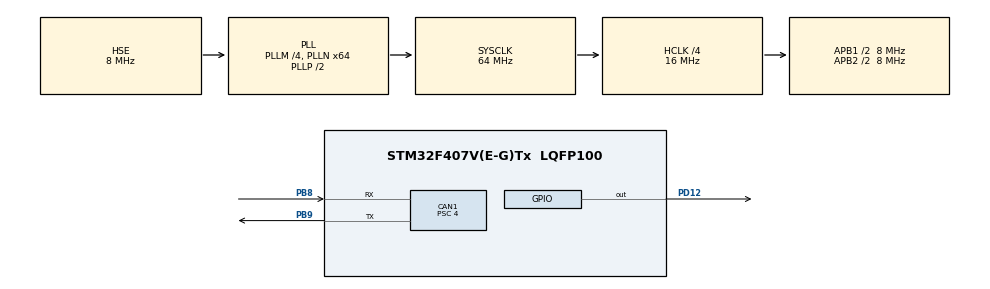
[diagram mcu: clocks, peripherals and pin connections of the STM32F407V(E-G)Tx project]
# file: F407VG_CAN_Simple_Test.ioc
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CAN1.BS1=CAN_BS1_2TQ
CAN1.CalculateTimeQuantum=500.0
CAN1.Mode=CAN_MODE_NORMAL
CAN1.NART=ENABLE
CAN1.Prescaler=4
CAN1.SJW=CAN_SJW_1TQ
Mcu.Family=STM32F4
Mcu.Name=STM32F407V(E-G)Tx
Mcu.Package=LQFP100
NVIC.PriorityGroup=NVIC_PRIORITYGROUP_4
NVIC.TIM1_UP_TIM10_IRQn=true\:0\:0\:false\:false\:true\:false\:true
NVIC.TimeBase=TIM1_UP_TIM10_IRQn
NVIC.TimeBaseIP=TIM1
PA13.Mode=Trace_Asynchronous_SW
PA13.Signal=SYS_JTMS-SWDIO
PA14.Mode=Trace_Asynchronous_SW
PA14.Signal=SYS_JTCK-SWCLK
PB3.Mode=Trace_Asynchronous_SW
PB3.Signal=SYS_JTDO-SWO
PB8.Mode=Master
PB8.Signal=CAN1_RX
PB9.Mode=Master
PB9.Signal=CAN1_TX
PD12.Signal=GPIO_Output
PH0-OSC_IN.Mode=HSE-External-Oscillator
PH0-OSC_IN.Signal=RCC_OSC_IN
PH1-OSC_OUT.Mode=HSE-External-Oscillator
PH1-OSC_OUT.Signal=RCC_OSC_OUT
ProjectManager.HeapSize=0x200
ProjectManager.StackSize=0x400
ProjectManager.TargetToolchain=STM32CubeIDE
RCC.48MHZClocksFreq_Value=32000000
RCC.AHBCLKDivider=RCC_SYSCLK_DIV4
RCC.AHBFreq_Value=16000000
RCC.APB1CLKDivider=RCC_HCLK_DIV2
RCC.APB1Freq_Value=8000000
RCC.APB1TimFreq_Value=16000000
RCC.APB2CLKDivider=RCC_HCLK_DIV2
RCC.APB2Freq_Value=8000000
RCC.APB2TimFreq_Value=16000000
RCC.CortexFreq_Value=16000000
RCC.HCLKFreq_Value=16000000
RCC.HSE_VALUE=8000000
RCC.HSI_VALUE=16000000
RCC.LSE_VALUE=32768
RCC.PLLM=4
RCC.PLLN=64
RCC.PLLSourceVirtual=RCC_PLLSOURCE_HSE
RCC.SYSCLKFreq_VALUE=64000000
RCC.SYSCLKSource=RCC_SYSCLKSOURCE_PLLCLK
RCC.VCOOutputFreq_Value=128000000
VP_SYS_VS_tim1.Mode=TIM1
board=custom

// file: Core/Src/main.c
/* USER CODE BEGIN Header */
/**
  ******************************************************************************
  * @file           : main.c
  * @brief          : Main program body
  ******************************************************************************
  * @attention
  *
  * <h2><center>&copy; Copyright (c) 2020 STMicroelectronics.
  * All rights reserved.</center></h2>
  *
  * This software component is licensed by ST under BSD 3-Clause license,
  * the "License"; You may not use this file except in compliance with the
  * License. You may obtain a copy of the License at:
  *                        opensource.org/licenses/BSD-3-Clause
  *
  ******************************************************************************
  */
/* USER CODE END Header */

#include "main.h"
#include "can.h"
#include "gpio.h"

/* USER CODE BEGIN Includes */
#include <stdio.h>
/* USER CODE END Includes */

/* USER CODE BEGIN PTD */
//class A
//{
//public:
//	A(){};
//
//	int x;
//};
/* USER CODE END PTD */

void SystemClock_Config(void);

int main(void)
{

  /* MCU Configuration--------------------------------------------------------*/

  /* Reset of all peripherals, Initializes the Flash interface and the Systick. */
  HAL_Init();

  /* Configure the system clock */
  SystemClock_Config();

  /* Initialize all configured peripherals */
  MX_GPIO_Init();
  MX_CAN1_Init();
  /* USER CODE BEGIN 2 */
  HAL_CAN_Start(&hcan1);
  /* USER CODE END 2 */

  /* Infinite loop */
  /* USER CODE BEGIN WHILE */
  while (1)
  {
	  CAN_TxHeaderTypeDef   TxHeader;
	  CAN_RxHeaderTypeDef   RxHeader;
	  uint8_t               TxData[8];
	  uint8_t               RxData[8];
	  uint32_t              TxMailbox;

	  static uint8_t count = 0;
	  TxHeader.StdId = 0x11;
	  TxHeader.RTR = CAN_RTR_DATA;
	  TxHeader.IDE = CAN_ID_STD;
	  TxHeader.DLC = 2;
	  TxHeader.TransmitGlobalTime = DISABLE;
	  TxData[0] = 0xCA;
	  TxData[1] = count++;

	  HAL_CAN_AddTxMessage(&hcan1, &TxHeader, TxData, &TxMailbox);

	  HAL_Delay(100);

	  CAN_FilterTypeDef  sFilterConfig;
	  sFilterConfig.FilterBank = 0;
	  sFilterConfig.FilterMode = CAN_FILTERMODE_IDMASK;
	  sFilterConfig.FilterScale = CAN_FILTERSCALE_16BIT;
	  sFilterConfig.FilterIdHigh = 0x0000;
	  sFilterConfig.FilterIdLow = 0x0000;
	  sFilterConfig.FilterMaskIdHigh = 0x0000;
	  sFilterConfig.FilterMaskIdLow = 0x0000;
	  sFilterConfig.FilterFIFOAssignment = CAN_RX_FIFO0;
	  sFilterConfig.FilterActivation = ENABLE;
	  sFilterConfig.SlaveStartFilterBank = 14;

	  HAL_CAN_ConfigFilter(&hcan1, &sFilterConfig);

	  uint8_t fifo0;
	  fifo0 = HAL_CAN_GetRxFifoFillLevel(&hcan1, 0);
	  uint8_t fifo1;
	  fifo1 = HAL_CAN_GetRxFifoFillLevel(&hcan1, 1);
	  printf("FIFO0 available %d\r\n", fifo0);
	  printf("FIFO1 available %d\r\n", fifo1);
	  HAL_CAN_GetRxMessage(&hcan1, 0, &RxHeader, RxData);
	  printf("Data FIFI0: %x %x %x\r\n", RxHeader.StdId, RxData[0], RxData[1]);
//	  printf("xx: \r\n");

	  HAL_Delay(2000);

    /* USER CODE END WHILE */

  }
}

void SystemClock_Config(void)
{
  RCC_OscInitTypeDef RCC_OscInitStruct = {0};
  RCC_ClkInitTypeDef RCC_ClkInitStruct = {0};

  /** Configure the main internal regulator output voltage
  */
  __HAL_RCC_PWR_CLK_ENABLE();
  __HAL_PWR_VOLTAGESCALING_CONFIG(PWR_REGULATOR_VOLTAGE_SCALE1);
  /** Initializes the CPU, AHB and APB busses clocks
  */
  RCC_OscInitStruct.OscillatorType = RCC_OSCILLATORTYPE_HSE;
  RCC_OscInitStruct.HSEState = RCC_HSE_ON;
  RCC_OscInitStruct.PLL.PLLState = RCC_PLL_ON;
  RCC_OscInitStruct.PLL.PLLSource = RCC_PLLSOURCE_HSE;
  RCC_OscInitStruct.PLL.PLLM = 4;
  RCC_OscInitStruct.PLL.PLLN = 64;
  RCC_OscInitStruct.PLL.PLLP = RCC_PLLP_DIV2;
  RCC_OscInitStruct.PLL.PLLQ = 4;
  if (HAL_RCC_OscConfig(&RCC_OscInitStruct) != HAL_OK)
  {
    Error_Handler();
  }
  /** Initializes the CPU, AHB and APB busses clocks
  */
  RCC_ClkInitStruct.ClockType = RCC_CLOCKTYPE_HCLK|RCC_CLOCKTYPE_SYSCLK
                              |RCC_CLOCKTYPE_PCLK1|RCC_CLOCKTYPE_PCLK2;
  RCC_ClkInitStruct.SYSCLKSource = RCC_SYSCLKSOURCE_PLLCLK;
  RCC_ClkInitStruct.AHBCLKDivider = RCC_SYSCLK_DIV4;
  RCC_ClkInitStruct.APB1CLKDivider = RCC_HCLK_DIV2;
  RCC_ClkInitStruct.APB2CLKDivider = RCC_HCLK_DIV2;

  if (HAL_RCC_ClockConfig(&RCC_ClkInitStruct, FLASH_LATENCY_0) != HAL_OK)
  {
    Error_Handler();
  }
}

/* USER CODE BEGIN 4 */
int _write(int file, char *ptr, int len)
{
  /* Implement your write code here, this is used by puts and printf for example */
  int i=0;
  for(i=0 ; i<len ; i++)
    ITM_SendChar((*ptr++));
  return len;
}
/* USER CODE END 4 */

 /**
  * @brief  Period elapsed callback in non blocking mode
  * @note   This function is called  when TIM1 interrupt took place, inside
  * HAL_TIM_IRQHandler(). It makes a direct call to HAL_IncTick() to increment
  * a global variable "uwTick" used as application time base.
  * @param  htim : TIM handle
  * @retval None
  */
void HAL_TIM_PeriodElapsedCallback(TIM_HandleTypeDef *htim)
{
  if (htim->Instance == TIM1) {
    HAL_IncTick();
  }
}

void Error_Handler(void)
{
}

/************************ (C) COPYRIGHT STMicroelectronics *****END OF FILE****/
